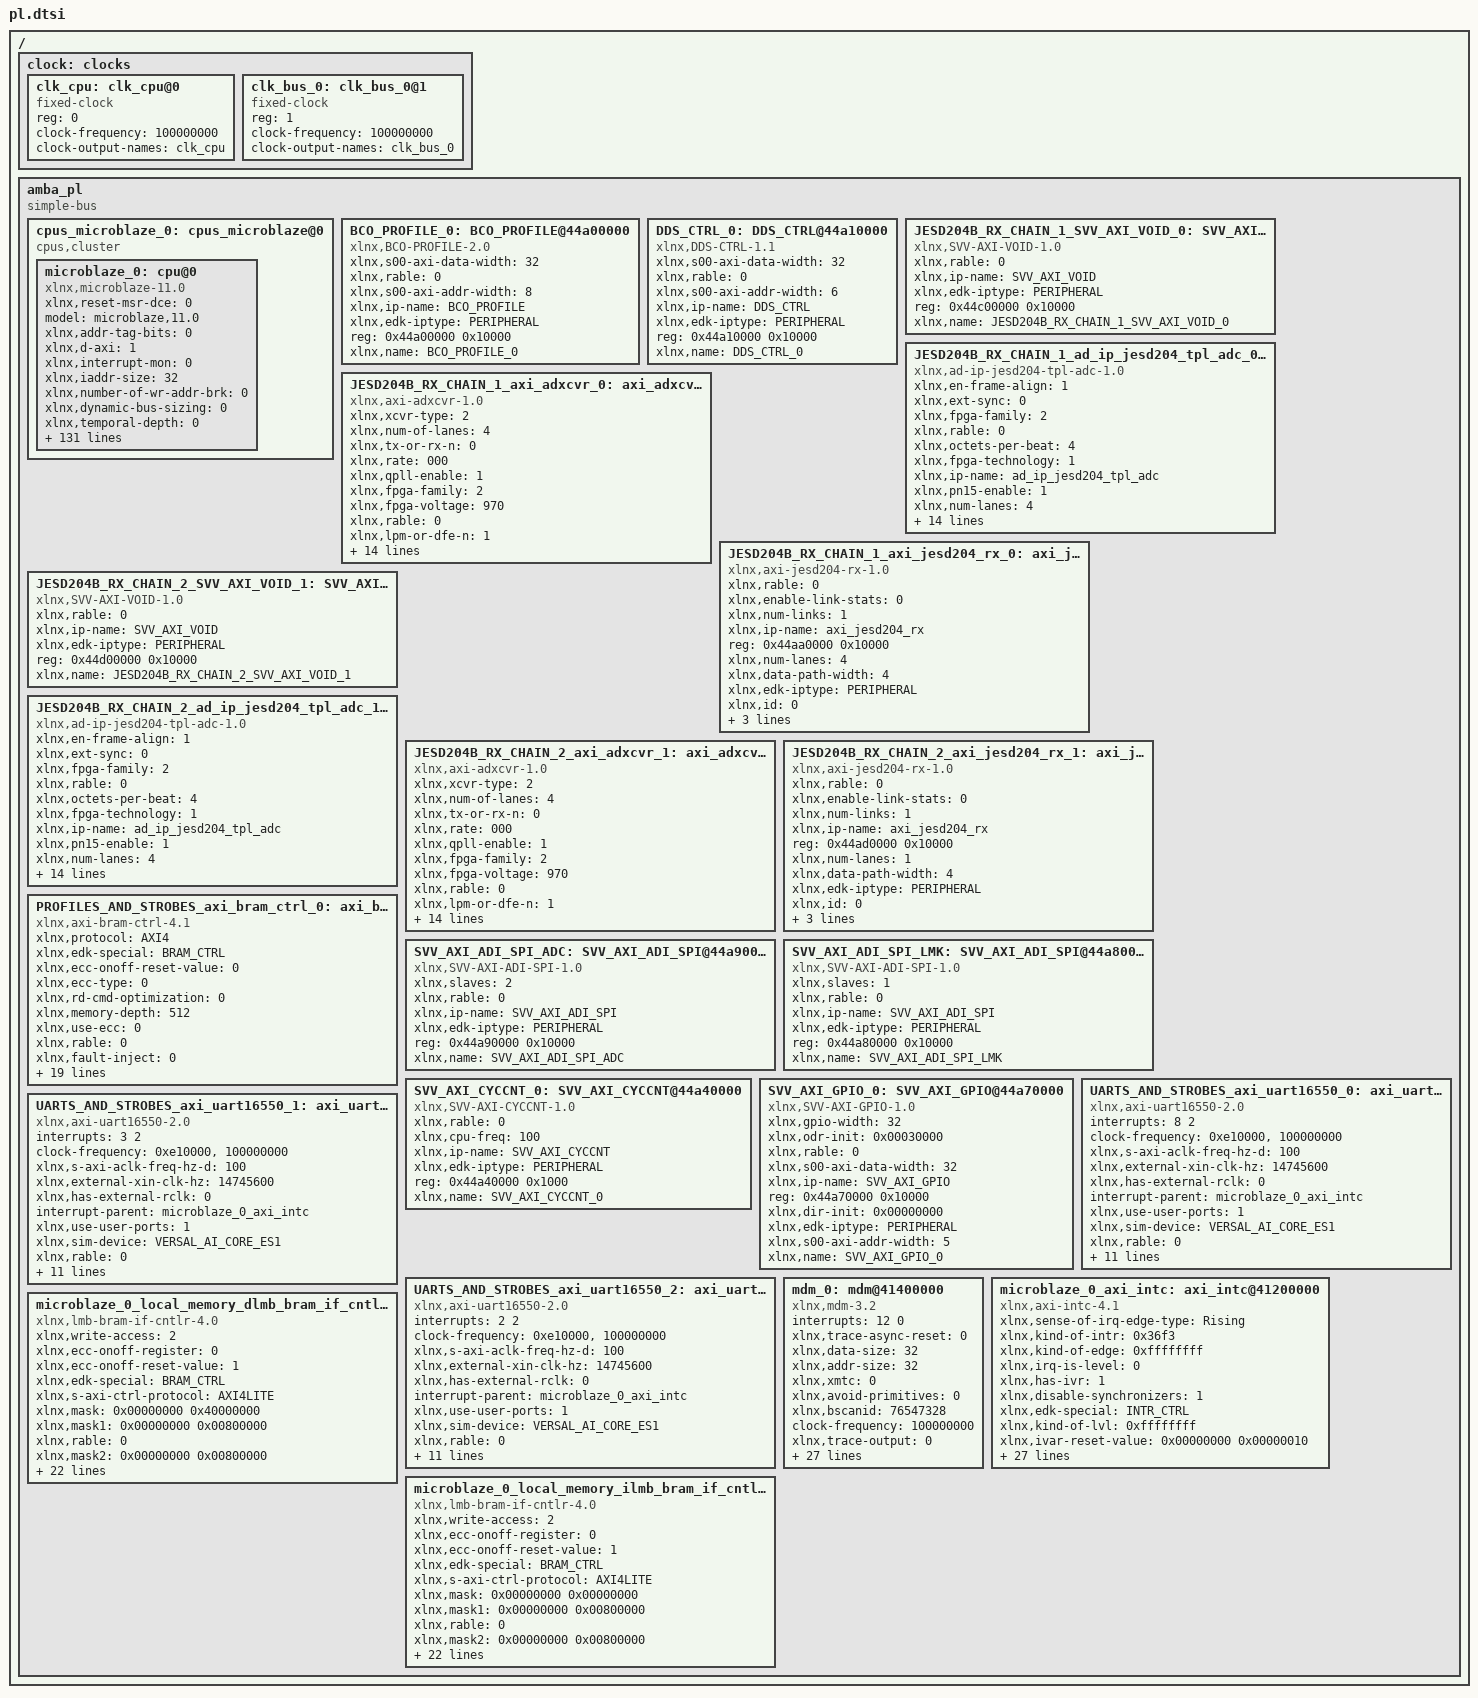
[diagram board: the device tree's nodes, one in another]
/ {
	clock: clocks {
		#address-cells = <1>;
		#size-cells = <0>;
		clk_cpu: clk_cpu@0 {
			compatible = "fixed-clock";
			reg = <0>;
			clock-frequency = <100000000>;
			clock-output-names = "clk_cpu";
			#clock-cells = <0>;
		};
		clk_bus_0: clk_bus_0@1 {
			compatible = "fixed-clock";
			reg = <1>;
			clock-frequency = <100000000>;
			clock-output-names = "clk_bus_0";
			#clock-cells = <0>;
		};
	};
	amba_pl: amba_pl {
		ranges;
		compatible = "simple-bus";
		#address-cells = <1>;
		#size-cells = <1>;
		cpus_microblaze_0: cpus_microblaze@0 {
			#cpu-mask-cells = <1>;
			compatible = "cpus,cluster";
			microblaze_0: cpu@0 {
				xlnx,reset-msr-dce = <0>;
				model = "microblaze,11.0";
				xlnx,addr-tag-bits = <0>;
				xlnx,d-axi = <1>;
				xlnx,interrupt-mon = <0>;
				xlnx,iaddr-size = <32>;
				xlnx,number-of-wr-addr-brk = <0>;
				xlnx,dynamic-bus-sizing = <0>;
				xlnx,temporal-depth = <0>;
				xlnx,rable = <0>;
				xlnx,use-interrupt = <2>;
				xlnx,optimization = <0>;
				xlnx,ip-axi-mon = <0>;
				xlnx,ip-name = "microblaze";
				d-cache-highaddr = <0x3fffffff>;
				xlnx,dcache-force-tag-lutram = <0>;
				xlnx,pc-width = <32>;
				xlnx,interrupt-is-edge = <1>;
				reg = <0x0>;
				xlnx,async-interrupt = <1>;
				xlnx,use-mmu = <0>;
				xlnx,reset-msr-ee = <0>;
				xlnx,icache-victims = <0>;
				xlnx,use-reorder-instr = <1>;
				xlnx,d-lmb-mon = <0>;
				xlnx,d-lmb-protocol = <0>;
				xlnx,ill-opcode-exception = <0>;
				xlnx,dcache-always-used = <1>;
				xlnx,use-div = <1>;
				xlnx,dc-axi-mon = <0>;
				xlnx,debug-trace-async-reset = <0>;
				xlnx,trace = <0>;
				xlnx,part = "xc7k410tffg900-2";
				i-cache-baseaddr = <0x00000000>;
				xlnx,use-config-reset = <0>;
				xlnx,pvr = <0>;
				xlnx,i-lmb-mon = <0>;
				xlnx,dcache-byte-size = <8192>;
				xlnx,fault-tolerant = <0>;
				xlnx,family = "kintex7";
				compatible = "xlnx,microblaze-11.0" , "xlnx,microblaze";
				xlnx,data-size = <32>;
				xlnx,mmu-zones = <16>;
				xlnx,debug-trace-size = <8192>;
				xlnx,mmu-privileged-instr = <0>;
				xlnx,enable-discrete-ports = <0>;
				d-cache-line-size = <16>;
				xlnx,d-lmb = <1>;
				xlnx,sco = <0>;
				xlnx,reset-msr-eip = <0>;
				clock-frequency = <100000000>;
				xlnx,debug-interface = <0>;
				xlnx,use-ext-brk = <0>;
				xlnx,daddr-size = <32>;
				xlnx,debug-enabled = <1>;
				xlnx,reset-msr-ice = <0>;
				xlnx,num-sync-ff-dbg-trace-clk = <2>;
				xlnx,i-lmb-protocol = <0>;
				xlnx,endianness = <1>;
				xlnx,fsl-exception = <0>;
				i-cache-line-size = <16>;
				xlnx,use-extended-fsl-instr = <0>;
				xlnx,reset-msr = <0x00000000>;
				xlnx,dp-axi-mon = <0>;
				xlnx,branch-target-cache-size = <0>;
				xlnx,dcache-use-writeback = <0>;
				xlnx,div-zero-exception = <0>;
				xlnx,mmu-tlb-access = <3>;
				bus-handle = <&amba_pl>;
				xlnx,cache-byte-size = <8192>;
				xlnx,pvr-user2 = <0x00000000>;
				xlnx,opcode-0x0-illegal = <0>;
				xlnx,icache-line-len = <4>;
				xlnx,ecc-use-ce-exception = <0>;
				xlnx,base-vectors = <0x00000000 0x00000000>;
				xlnx,use-dcache = <0>;
				xlnx,use-barrel = <1>;
				xlnx,reset-msr-bip = <0>;
				xlnx,edk-special = "microblaze";
				xlnx,allow-dcache-wr = <1>;
				xlnx,addr-size = <32>;
				xlnx,debug-external-trace = <0>;
				xlnx,piaddr-size = <32>;
				i-cache-highaddr = <0x3fffffff>;
				xlnx,num-sync-ff-clk-debug = <2>;
				xlnx,debug-event-counters = <5>;
				xlnx,fpu-exception = <0>;
				xlnx,allow-icache-wr = <1>;
				xlnx,i-axi = <0>;
				xlnx,g-use-exceptions = <0>;
				xlnx,icache-streams = <0>;
				xlnx,g-template-list = <0>;
				xlnx,dcache-line-len = <4>;
				xlnx,num-sync-ff-clk = <2>;
				xlnx,use-stack-protection = <0>;
				xlnx,use-hw-mul = <2>;
				xlnx,num-sync-ff-dbg-clk = <1>;
				xlnx,interconnect = <2>;
				xlnx,edk-iptype = "PROCESSOR";
				xlnx,debug-latency-counters = <1>;
				i-cache-size = <8192>;
				xlnx,use-fpu = <0>;
				xlnx,reset-msr-ie = <0>;
				xlnx,edge-is-positive = <1>;
				xlnx,use-pcmp-instr = <1>;
				xlnx,use-icache = <0>;
				d-cache-size = <8192>;
				xlnx,async-wakeup = <3>;
				xlnx,use-non-secure = <0>;
				xlnx,dcache-addr-tag = <0>;
				xlnx,number-of-rd-addr-brk = <0>;
				d-cache-baseaddr = <0x00000000>;
				xlnx,area-optimized = <0>;
				xlnx,avoid-primitives = <0>;
				xlnx,lockstep-slave = <0>;
				xlnx,use-ext-nm-brk = <0>;
				xlnx,instr-size = <32>;
				interrupt-handle = <&microblaze_0_axi_intc>;
				xlnx,icache-always-used = <1>;
				xlnx,i-lmb = <1>;
				xlnx,mmu-dtlb-size = <4>;
				xlnx,lockstep-select = <0>;
				xlnx,lmb-data-size = <32>;
				xlnx,ic-axi-mon = <0>;
				xlnx,num-sync-ff-clk-irq = <1>;
				xlnx,fsl-links = <0>;
				timebase-frequency = <100000000>;
				xlnx,icache-force-tag-lutram = <0>;
				xlnx,dcache-data-width = <0>;
				xlnx,dcache-victims = <0>;
				xlnx,use-branch-target-cache = <0>;
				xlnx,debug-profile-size = <0>;
				xlnx,unaligned-exceptions = <0>;
				xlnx,lockstep-master = <0>;
				xlnx,freq = <100000000>;
				xlnx,number-of-pc-brk = <1>;
				xlnx,mmu-itlb-size = <2>;
				xlnx,imprecise-exceptions = <0>;
				xlnx,use-msr-instr = <1>;
				xlnx,icache-data-width = <0>;
				xlnx,debug-counter-width = <32>;
			};
		};
		BCO_PROFILE_0: BCO_PROFILE@44a00000 {
			xlnx,s00-axi-data-width = <32>;
			xlnx,rable = <0>;
			compatible = "xlnx,BCO-PROFILE-2.0";
			status = "okay";
			xlnx,s00-axi-addr-width = <8>;
			xlnx,ip-name = "BCO_PROFILE";
			xlnx,edk-iptype = "PERIPHERAL";
			reg = <0x44a00000 0x10000>;
			xlnx,name = "BCO_PROFILE_0";
		};
		DDS_CTRL_0: DDS_CTRL@44a10000 {
			xlnx,s00-axi-data-width = <32>;
			xlnx,rable = <0>;
			compatible = "xlnx,DDS-CTRL-1.1";
			status = "okay";
			xlnx,s00-axi-addr-width = <6>;
			xlnx,ip-name = "DDS_CTRL";
			xlnx,edk-iptype = "PERIPHERAL";
			reg = <0x44a10000 0x10000>;
			xlnx,name = "DDS_CTRL_0";
		};
		JESD204B_RX_CHAIN_1_SVV_AXI_VOID_0: SVV_AXI_VOID@44c00000 {
			xlnx,rable = <0>;
			compatible = "xlnx,SVV-AXI-VOID-1.0";
			status = "okay";
			xlnx,ip-name = "SVV_AXI_VOID";
			xlnx,edk-iptype = "PERIPHERAL";
			reg = <0x44c00000 0x10000>;
			xlnx,name = "JESD204B_RX_CHAIN_1_SVV_AXI_VOID_0";
		};
		JESD204B_RX_CHAIN_1_ad_ip_jesd204_tpl_adc_0: ad_ip_jesd204_tpl_adc@44ab0000 {
			compatible = "xlnx,ad-ip-jesd204-tpl-adc-1.0";
			xlnx,en-frame-align = <1>;
			xlnx,ext-sync = <0>;
			xlnx,fpga-family = <2>;
			xlnx,rable = <0>;
			xlnx,octets-per-beat = <4>;
			xlnx,fpga-technology = <1>;
			xlnx,ip-name = "ad_ip_jesd204_tpl_adc";
			xlnx,pn15-enable = <1>;
			xlnx,num-lanes = <4>;
			reg = <0x44ab0000 0x10000>;
			xlnx,dev-package = <3>;
			xlnx,speed-grade = <20>;
			xlnx,samples-per-frame = <1>;
			xlnx,pn7-enable = <1>;
			xlnx,num-channels = <2>;
			xlnx,dma-bits-per-sample = <16>;
			xlnx,edk-iptype = "PERIPHERAL";
			xlnx,id = <0>;
			xlnx,bits-per-sample = <16>;
			xlnx,twos-complement = <1>;
			status = "okay";
			xlnx,name = "JESD204B_RX_CHAIN_1_ad_ip_jesd204_tpl_adc_0";
			xlnx,converter-resolution = <14>;
		};
		JESD204B_RX_CHAIN_1_axi_adxcvr_0: axi_adxcvr@44a60000 {
			xlnx,xcvr-type = <2>;
			xlnx,num-of-lanes = <4>;
			compatible = "xlnx,axi-adxcvr-1.0";
			xlnx,tx-or-rx-n = <0>;
			xlnx,rate = "000";
			xlnx,qpll-enable = <1>;
			xlnx,fpga-family = <2>;
			xlnx,fpga-voltage = <970>;
			xlnx,rable = <0>;
			xlnx,lpm-or-dfe-n = <1>;
			xlnx,tx-diffctrl = "01000";
			xlnx,ip-name = "axi_adxcvr";
			xlnx,fpga-technology = <1>;
			xlnx,out-clk-sel = "100";
			reg = <0x44a60000 0x10000>;
			xlnx,dev-package = <3>;
			xlnx,speed-grade = <20>;
			xlnx,edk-iptype = "PERIPHERAL";
			xlnx,tx-postcursor = "00000";
			xlnx,id = <0>;
			xlnx,tx-precursor = "00000";
			status = "okay";
			xlnx,sys-clk-sel = "11";
			xlnx,link-mode = <1>;
			xlnx,name = "JESD204B_RX_CHAIN_1_axi_adxcvr_0";
		};
		JESD204B_RX_CHAIN_1_axi_jesd204_rx_0: axi_jesd204_rx@44aa0000 {
			compatible = "xlnx,axi-jesd204-rx-1.0";
			xlnx,rable = <0>;
			xlnx,enable-link-stats = <0>;
			xlnx,num-links = <1>;
			xlnx,ip-name = "axi_jesd204_rx";
			reg = <0x44aa0000 0x10000>;
			xlnx,num-lanes = <4>;
			xlnx,data-path-width = <4>;
			xlnx,edk-iptype = "PERIPHERAL";
			xlnx,id = <0>;
			status = "okay";
			xlnx,link-mode = <1>;
			xlnx,name = "JESD204B_RX_CHAIN_1_axi_jesd204_rx_0";
		};
		JESD204B_RX_CHAIN_2_SVV_AXI_VOID_1: SVV_AXI_VOID@44d00000 {
			xlnx,rable = <0>;
			compatible = "xlnx,SVV-AXI-VOID-1.0";
			status = "okay";
			xlnx,ip-name = "SVV_AXI_VOID";
			xlnx,edk-iptype = "PERIPHERAL";
			reg = <0x44d00000 0x10000>;
			xlnx,name = "JESD204B_RX_CHAIN_2_SVV_AXI_VOID_1";
		};
		JESD204B_RX_CHAIN_2_ad_ip_jesd204_tpl_adc_1: ad_ip_jesd204_tpl_adc@44ae0000 {
			compatible = "xlnx,ad-ip-jesd204-tpl-adc-1.0";
			xlnx,en-frame-align = <1>;
			xlnx,ext-sync = <0>;
			xlnx,fpga-family = <2>;
			xlnx,rable = <0>;
			xlnx,octets-per-beat = <4>;
			xlnx,fpga-technology = <1>;
			xlnx,ip-name = "ad_ip_jesd204_tpl_adc";
			xlnx,pn15-enable = <1>;
			xlnx,num-lanes = <4>;
			reg = <0x44ae0000 0x10000>;
			xlnx,dev-package = <3>;
			xlnx,speed-grade = <20>;
			xlnx,samples-per-frame = <1>;
			xlnx,pn7-enable = <1>;
			xlnx,num-channels = <2>;
			xlnx,dma-bits-per-sample = <16>;
			xlnx,edk-iptype = "PERIPHERAL";
			xlnx,id = <0>;
			xlnx,bits-per-sample = <16>;
			xlnx,twos-complement = <1>;
			status = "okay";
			xlnx,name = "JESD204B_RX_CHAIN_2_ad_ip_jesd204_tpl_adc_1";
			xlnx,converter-resolution = <14>;
		};
		JESD204B_RX_CHAIN_2_axi_adxcvr_1: axi_adxcvr@44ac0000 {
			xlnx,xcvr-type = <2>;
			xlnx,num-of-lanes = <4>;
			compatible = "xlnx,axi-adxcvr-1.0";
			xlnx,tx-or-rx-n = <0>;
			xlnx,rate = "000";
			xlnx,qpll-enable = <1>;
			xlnx,fpga-family = <2>;
			xlnx,fpga-voltage = <970>;
			xlnx,rable = <0>;
			xlnx,lpm-or-dfe-n = <1>;
			xlnx,tx-diffctrl = "01000";
			xlnx,ip-name = "axi_adxcvr";
			xlnx,fpga-technology = <1>;
			xlnx,out-clk-sel = "100";
			reg = <0x44ac0000 0x10000>;
			xlnx,dev-package = <3>;
			xlnx,speed-grade = <20>;
			xlnx,edk-iptype = "PERIPHERAL";
			xlnx,tx-postcursor = "00000";
			xlnx,id = <0>;
			xlnx,tx-precursor = "00000";
			status = "okay";
			xlnx,sys-clk-sel = "11";
			xlnx,link-mode = <1>;
			xlnx,name = "JESD204B_RX_CHAIN_2_axi_adxcvr_1";
		};
		JESD204B_RX_CHAIN_2_axi_jesd204_rx_1: axi_jesd204_rx@44ad0000 {
			compatible = "xlnx,axi-jesd204-rx-1.0";
			xlnx,rable = <0>;
			xlnx,enable-link-stats = <0>;
			xlnx,num-links = <1>;
			xlnx,ip-name = "axi_jesd204_rx";
			reg = <0x44ad0000 0x10000>;
			xlnx,num-lanes = <1>;
			xlnx,data-path-width = <4>;
			xlnx,edk-iptype = "PERIPHERAL";
			xlnx,id = <0>;
			status = "okay";
			xlnx,link-mode = <1>;
			xlnx,name = "JESD204B_RX_CHAIN_2_axi_jesd204_rx_1";
		};
		PROFILES_AND_STROBES_axi_bram_ctrl_0: axi_bram_ctrl@c2000000 {
			xlnx,protocol = "AXI4";
			xlnx,edk-special = "BRAM_CTRL";
			compatible = "xlnx,axi-bram-ctrl-4.1";
			xlnx,ecc-onoff-reset-value = <0>;
			xlnx,ecc-type = <0>;
			xlnx,rd-cmd-optimization = <0>;
			xlnx,memory-depth = <512>;
			xlnx,use-ecc = <0>;
			xlnx,rable = <0>;
			xlnx,fault-inject = <0>;
			xlnx,ip-name = "axi_bram_ctrl";
			reg = <0xc2000000 0x1000>;
			xlnx,bmg-instance = "EXTERNAL";
			xlnx,s-axi-ctrl-addr-width = <32>;
			xlnx,read-latency = <1>;
			xlnx,s-axi-supports-narrow-burst = <0>;
			xlnx,id-width = <0>;
			xlnx,supports-narrow-burst = <0>;
			xlnx,single-port-bram = <1>;
			xlnx,ecc = <0>;
			xlnx,edk-iptype = "PERIPHERAL";
			status = "okay";
			xlnx,bram-addr-width = <9>;
			xlnx,bram-inst-mode = "EXTERNAL";
			xlnx,data-width = <512>;
			xlnx,s-axi-ctrl-data-width = <32>;
			xlnx,s-axi-id-width = <1>;
			xlnx,mem-depth = <512>;
			xlnx,name = "PROFILES_AND_STROBES_axi_bram_ctrl_0";
		};
		SVV_AXI_ADI_SPI_ADC: SVV_AXI_ADI_SPI@44a90000 {
			xlnx,slaves = <2>;
			xlnx,rable = <0>;
			compatible = "xlnx,SVV-AXI-ADI-SPI-1.0";
			status = "okay";
			xlnx,ip-name = "SVV_AXI_ADI_SPI";
			xlnx,edk-iptype = "PERIPHERAL";
			reg = <0x44a90000 0x10000>;
			xlnx,name = "SVV_AXI_ADI_SPI_ADC";
		};
		SVV_AXI_ADI_SPI_LMK: SVV_AXI_ADI_SPI@44a80000 {
			xlnx,slaves = <1>;
			xlnx,rable = <0>;
			compatible = "xlnx,SVV-AXI-ADI-SPI-1.0";
			status = "okay";
			xlnx,ip-name = "SVV_AXI_ADI_SPI";
			xlnx,edk-iptype = "PERIPHERAL";
			reg = <0x44a80000 0x10000>;
			xlnx,name = "SVV_AXI_ADI_SPI_LMK";
		};
		SVV_AXI_CYCCNT_0: SVV_AXI_CYCCNT@44a40000 {
			xlnx,rable = <0>;
			compatible = "xlnx,SVV-AXI-CYCCNT-1.0";
			status = "okay";
			xlnx,cpu-freq = <100>;
			xlnx,ip-name = "SVV_AXI_CYCCNT";
			xlnx,edk-iptype = "PERIPHERAL";
			reg = <0x44a40000 0x1000>;
			xlnx,name = "SVV_AXI_CYCCNT_0";
		};
		SVV_AXI_GPIO_0: SVV_AXI_GPIO@44a70000 {
			compatible = "xlnx,SVV-AXI-GPIO-1.0";
			xlnx,gpio-width = <32>;
			xlnx,odr-init = <0x00030000>;
			xlnx,rable = <0>;
			xlnx,s00-axi-data-width = <32>;
			xlnx,ip-name = "SVV_AXI_GPIO";
			reg = <0x44a70000 0x10000>;
			xlnx,dir-init = <0x00000000>;
			xlnx,edk-iptype = "PERIPHERAL";
			status = "okay";
			xlnx,s00-axi-addr-width = <5>;
			xlnx,name = "SVV_AXI_GPIO_0";
		};
		UARTS_AND_STROBES_axi_uart16550_0: axi_uart16550@44a20000 {
			interrupts = < 8 2 >;
			compatible = "xlnx,axi-uart16550-2.0";
			clock-frequency = <0xe10000> , <100000000>;
			xlnx,s-axi-aclk-freq-hz-d = <100>;
			xlnx,external-xin-clk-hz = <14745600>;
			xlnx,has-external-rclk = <0>;
			interrupt-parent = <&microblaze_0_axi_intc>;
			xlnx,use-user-ports = <1>;
			xlnx,sim-device = "VERSAL_AI_CORE_ES1";
			xlnx,rable = <0>;
			xlnx,uart-board-interface = "Custom";
			xlnx,ip-name = "axi_uart16550";
			reg = <0x44a20000 0x10000>;
			xlnx,has-external-xin = <1>;
			clocks = <&clk_bus_0>;
			xlnx,use-modem-ports = <1>;
			xlnx,edk-iptype = "PERIPHERAL";
			status = "okay";
			xlnx,external-xin-clk-hz-d = <0xe10000>;
			xlnx,base-user = <1>;
			interrupt-names = "ip2intc_irpt";
			xlnx,is-a-16550 = <1>;
			xlnx,name = "UARTS_AND_STROBES_axi_uart16550_0";
		};
		UARTS_AND_STROBES_axi_uart16550_1: axi_uart16550@44a30000 {
			interrupts = < 3 2 >;
			compatible = "xlnx,axi-uart16550-2.0";
			clock-frequency = <0xe10000> , <100000000>;
			xlnx,s-axi-aclk-freq-hz-d = <100>;
			xlnx,external-xin-clk-hz = <14745600>;
			xlnx,has-external-rclk = <0>;
			interrupt-parent = <&microblaze_0_axi_intc>;
			xlnx,use-user-ports = <1>;
			xlnx,sim-device = "VERSAL_AI_CORE_ES1";
			xlnx,rable = <0>;
			xlnx,uart-board-interface = "Custom";
			xlnx,ip-name = "axi_uart16550";
			reg = <0x44a30000 0x10000>;
			xlnx,has-external-xin = <1>;
			clocks = <&clk_bus_0>;
			xlnx,use-modem-ports = <1>;
			xlnx,edk-iptype = "PERIPHERAL";
			status = "okay";
			xlnx,external-xin-clk-hz-d = <0xe10000>;
			xlnx,base-user = <1>;
			interrupt-names = "ip2intc_irpt";
			xlnx,is-a-16550 = <1>;
			xlnx,name = "UARTS_AND_STROBES_axi_uart16550_1";
		};
		UARTS_AND_STROBES_axi_uart16550_2: axi_uart16550@44a50000 {
			interrupts = < 2 2 >;
			compatible = "xlnx,axi-uart16550-2.0";
			clock-frequency = <0xe10000> , <100000000>;
			xlnx,s-axi-aclk-freq-hz-d = <100>;
			xlnx,external-xin-clk-hz = <14745600>;
			xlnx,has-external-rclk = <0>;
			interrupt-parent = <&microblaze_0_axi_intc>;
			xlnx,use-user-ports = <1>;
			xlnx,sim-device = "VERSAL_AI_CORE_ES1";
			xlnx,rable = <0>;
			xlnx,uart-board-interface = "Custom";
			xlnx,ip-name = "axi_uart16550";
			reg = <0x44a50000 0x10000>;
			xlnx,has-external-xin = <1>;
			clocks = <&clk_bus_0>;
			xlnx,use-modem-ports = <1>;
			xlnx,edk-iptype = "PERIPHERAL";
			status = "okay";
			xlnx,external-xin-clk-hz-d = <0xe10000>;
			xlnx,base-user = <1>;
			interrupt-names = "ip2intc_irpt";
			xlnx,is-a-16550 = <1>;
			xlnx,name = "UARTS_AND_STROBES_axi_uart16550_2";
		};
		mdm_0: mdm@41400000 {
			interrupts = < 12 0 >;
			xlnx,trace-async-reset = <0>;
			compatible = "xlnx,mdm-3.2" , "xlnx,xps-uartlite-1.00.a";
			xlnx,data-size = <32>;
			xlnx,addr-size = <32>;
			xlnx,xmtc = <0>;
			xlnx,avoid-primitives = <0>;
			xlnx,bscanid = <76547328>;
			clock-frequency = <100000000>;
			xlnx,trace-output = <0>;
			xlnx,debug-interface = <0>;
			interrupt-parent = <&microblaze_0_axi_intc>;
			xlnx,use-uart = <1>;
			xlnx,rable = <0>;
			xlnx,mb-dbg-ports = <1>;
			xlnx,jtag-chain = <2>;
			xlnx,ext-trig-reset-value = <0xF1234>;
			xlnx,trig-in-ports = <1>;
			xlnx,ip-name = "mdm";
			xlnx,brk = <0>;
			xlnx,dbg-reg-access = <0>;
			reg = <0x41400000 0x1000>;
			clocks = <&clk_bus_0>;
			xlnx,use-bscan = <0>;
			xlnx,trace-id = <110>;
			xlnx,lmb-protocol = <0>;
			xlnx,trace-data-width = <32>;
			xlnx,interconnect = <2>;
			xlnx,edk-iptype = "PERIPHERAL";
			xlnx,use-cross-trigger = <0>;
			xlnx,trace-protocol = <1>;
			status = "okay";
			interrupt-names = "Interrupt";
			xlnx,use-config-reset = <0>;
			xlnx,trig-out-ports = <1>;
			xlnx,device = "xc7k410t";
			xlnx,dbg-mem-access = <0>;
			xlnx,trace-clk-out-phase = <90>;
			xlnx,name = "mdm_0";
		};
		microblaze_0_axi_intc: axi_intc@41200000 {
			#interrupt-cells = <2>;
			xlnx,sense-of-irq-edge-type = "Rising";
			xlnx,kind-of-intr = <0x36f3>;
			xlnx,kind-of-edge = <0xffffffff>;
			xlnx,irq-is-level = <0>;
			xlnx,has-ivr = <1>;
			compatible = "xlnx,axi-intc-4.1" , "xlnx,xps-intc-1.00.a";
			xlnx,disable-synchronizers = <1>;
			xlnx,edk-special = "INTR_CTRL";
			xlnx,kind-of-lvl = <0xffffffff>;
			xlnx,ivar-reset-value = <0x00000000 0x00000010>;
			xlnx,irq-active = <0x1>;
			xlnx,rable = <0>;
			xlnx,en-cascade-mode = <0>;
			xlnx,ip-name = "axi_intc";
			xlnx,has-ilr = <0>;
			reg = <0x41200000 0x10000>;
			xlnx,addr-width = <0x20>;
			xlnx,s-axi-aclk-freq-mhz = <100>;
			xlnx,num-sw-intr = <0>;
			xlnx,irq-connection = <0>;
			xlnx,num-intr-inputs = <0xf>;
			xlnx,has-sie = <1>;
			xlnx,has-cie = <1>;
			xlnx,enable-async = <0>;
			xlnx,num-sync-ff = <2>;
			xlnx,mb-clk-not-connected = <1>;
			xlnx,has-ipr = <1>;
			xlnx,edk-iptype = "PERIPHERAL";
			xlnx,sense-of-irq-level-type = "Active_High";
			xlnx,cascade-master = <0>;
			xlnx,processor-clk-freq-mhz = <100>;
			status = "okay";
			xlnx,is-fast = <0x1>;
			xlnx,has-fast = <1>;
			xlnx,ivar-rst-val = <0x0000000000000010>;
			interrupt-controller;
			xlnx,async-intr = <0xFFFFBEF3>;
			xlnx,name = "microblaze_0_axi_intc";
		};
		microblaze_0_local_memory_dlmb_bram_if_cntlr: lmb_bram_if_cntlr@0 {
			xlnx,write-access = <2>;
			compatible = "xlnx,lmb-bram-if-cntlr-4.0";
			xlnx,ecc-onoff-register = <0>;
			xlnx,ecc-onoff-reset-value = <1>;
			xlnx,edk-special = "BRAM_CTRL";
			xlnx,s-axi-ctrl-protocol = "AXI4LITE";
			xlnx,mask = <0x00000000 0x40000000>;
			xlnx,mask1 = <0x00000000 0x00800000>;
			xlnx,rable = <0>;
			xlnx,mask2 = <0x00000000 0x00800000>;
			xlnx,fault-inject = <0>;
			xlnx,mask3 = <0x00000000 0x00800000>;
			xlnx,arbitration = <0>;
			xlnx,num-lmb = <1>;
			xlnx,mask4 = <0x00000000 0x00800000>;
			reg = <0x00000000 0x10000>;
			xlnx,s-axi-ctrl-addr-width = <32>;
			xlnx,mask5 = <0x00000000 0x00800000>;
			xlnx,ecc-status-registers = <0>;
			xlnx,mask6 = <0x00000000 0x00800000>;
			xlnx,lmb-protocol = <0>;
			xlnx,ce-counter-width = <0>;
			xlnx,mask7 = <0x00000000 0x00800000>;
			xlnx,ecc = <0>;
			xlnx,lmb-dwidth = <32>;
			xlnx,interconnect = <0>;
			xlnx,ce-failing-registers = <0>;
			xlnx,edk-iptype = "PERIPHERAL";
			xlnx,ue-failing-registers = <0>;
			xlnx,s-axi-ctrl-data-width = <32>;
			xlnx,bram-awidth = <32>;
			xlnx,lmb-awidth = <32>;
		};
		microblaze_0_local_memory_ilmb_bram_if_cntlr: lmb_bram_if_cntlr@1 {
			xlnx,write-access = <2>;
			compatible = "xlnx,lmb-bram-if-cntlr-4.0";
			xlnx,ecc-onoff-register = <0>;
			xlnx,ecc-onoff-reset-value = <1>;
			xlnx,edk-special = "BRAM_CTRL";
			xlnx,s-axi-ctrl-protocol = "AXI4LITE";
			xlnx,mask = <0x00000000 0x00000000>;
			xlnx,mask1 = <0x00000000 0x00800000>;
			xlnx,rable = <0>;
			xlnx,mask2 = <0x00000000 0x00800000>;
			xlnx,fault-inject = <0>;
			xlnx,mask3 = <0x00000000 0x00800000>;
			xlnx,arbitration = <0>;
			xlnx,num-lmb = <1>;
			xlnx,mask4 = <0x00000000 0x00800000>;
			reg = <0x00000000 0x4000>;
			xlnx,s-axi-ctrl-addr-width = <32>;
			xlnx,mask5 = <0x00000000 0x00800000>;
			xlnx,ecc-status-registers = <0>;
			xlnx,mask6 = <0x00000000 0x00800000>;
			xlnx,lmb-protocol = <0>;
			xlnx,ce-counter-width = <0>;
			xlnx,mask7 = <0x00000000 0x00800000>;
			xlnx,ecc = <0>;
			xlnx,lmb-dwidth = <32>;
			xlnx,interconnect = <0>;
			xlnx,ce-failing-registers = <0>;
			xlnx,edk-iptype = "PERIPHERAL";
			xlnx,ue-failing-registers = <0>;
			xlnx,s-axi-ctrl-data-width = <32>;
			xlnx,bram-awidth = <32>;
			xlnx,lmb-awidth = <32>;
		};
	};
};
